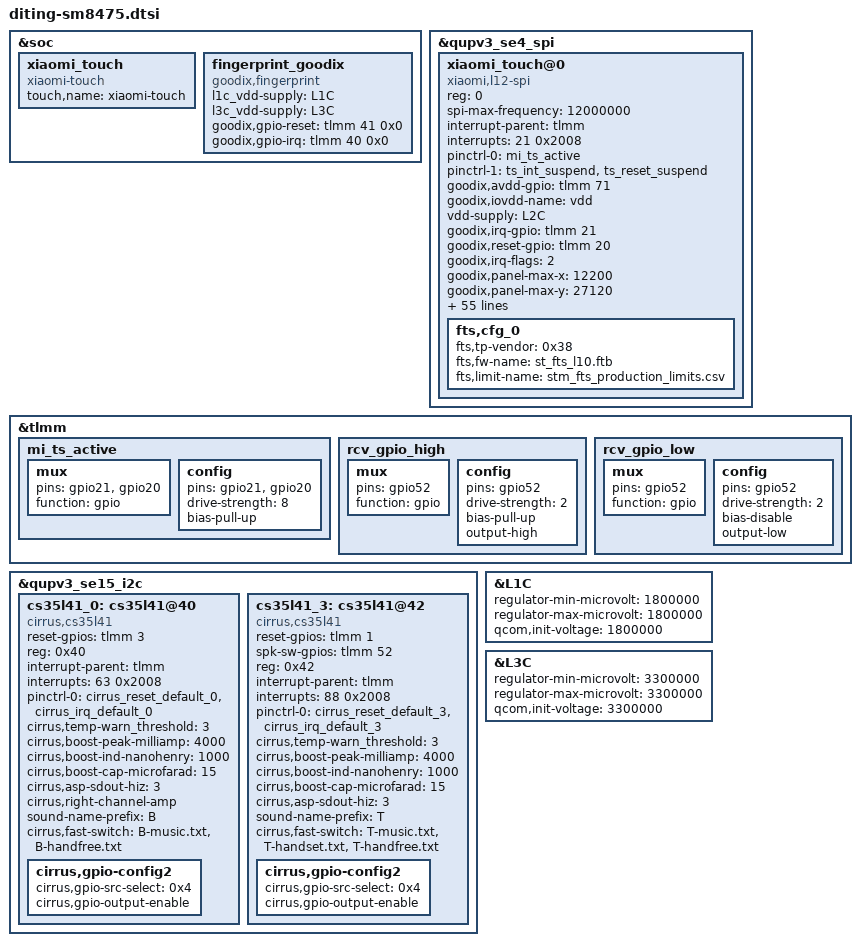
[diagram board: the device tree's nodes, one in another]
/*
   this file is for attribution only of unicorn
   And public attribution of xiaomi platforms(like K2 and so and)
*/
#include "diting-pinctrl.dtsi"
#include "xiaomi-sm8475-common.dtsi"
&soc {
	xiaomi_touch {
		compatible = "xiaomi-touch";
		status = "ok";
		touch,name = "xiaomi-touch";
	};
};
&qupv3_se4_spi {
	status = "ok";
	xiaomi_touch@0 {
		status = "ok";
		compatible = "xiaomi,l12-spi";
		reg = <0>;
		spi-max-frequency = <12000000>;
		interrupt-parent = <&tlmm>;
		interrupts = <21 0x2008>;
		//goodix,avdd-name = "avdd";
		//avdd-supply = <&L7C>;
		pinctrl-names = "pmx_ts_active", "pmx_ts_suspend";
		pinctrl-0 = <&mi_ts_active>;
		pinctrl-1 = <&ts_int_suspend &ts_reset_suspend>;

		goodix,avdd-gpio = <&tlmm 71 0x0>;
		goodix,iovdd-name = "vdd";
		vdd-supply = <&L2C>;
		goodix,irq-gpio = <&tlmm 21 0x2008>;
		goodix,reset-gpio = <&tlmm 20 0x00>;
		goodix,irq-flags = <2>;
		goodix,panel-max-x = <12200>;
		goodix,panel-max-y = <27120>;
		goodix,panel-max-w = <255>;
		goodix,panel-max-p = <4096>;
		goodix,firmware-name = "goodix_firmware_l12.bin";
		goodix,config-name = "goodix_cfg_group_l12.bin";


		fts,avdd-gpio = <&tlmm 71 0x0>;
		//avdd-supply = <&L3C>;
		//vdd-supply = <&L2C>;
		/*panel = <&dsi_k8_42_02_0a_dsc_cmd>;*/
		//fts,pwr-reg-name = "avdd";
		fts,bus-reg-name = "vdd";
		fts,irq-gpio = <&tlmm 21 0x2008>;
		fts,irq-gpio-name = "fts_irq";
		fts,reset-gpio-enable;
		fts,reset-gpio = <&tlmm 20 0x00>;
		fts,reset-gpio-name = "fts_rst";
		fts,irq-flags = <0x2008>;
		fts,x-max = <12200>;
		fts,y-max = <27120>;
		fts,swap-y;
		fts,swap-x;
		fts,support-fod = <1>;
		fts,fod-lx = <4960>;
		fts,fod-ly = <23300>;
		fts,fod-x-size = <2280>;
		fts,fod-y-size = <2280>;
		//spi-max-frequency = <12000000>;
		fts,default-fw-name = "st_fts_l12.ftb";
		//fts,htp-fw-name = "st_fts_l10_thp.ftb";
		fts,non-curved-display = <1>;
		fts,config-array-size = <1>;
		fts,support-super-resolution = <1>;
		fts,touch-follow-performance-def = <3>;
		fts,touch-tap-sensitivity-def = <4>;
		fts,touch-aim-sensitivity-def = <3>;
		fts,touch-tap-stability-def = <3>;
		fts,cornerfilter-area-step1 = <100>;
		fts,cornerfilter-area-step2 = <170>;
		fts,cornerfilter-area-step3 = <250>;
		fts,touch-edgezone-filter-ver = <1 0 0 0 0 0 0 0
						 1 1 0 0 0 0 0 0
						 1 2 0 0 40 2399 0 0
						 1 3 1039 0 1079 2399 0 0>;
		fts,touch-edgezone-filter-hor = <1 0 0 0 1079 40 0 0
						 1 1 0 2359 1079 2399 0 0
						 1 2 0 0 40 2399 0 0
						 1 3 1039 0 1079 2399 0 0>;
		fts,touch-cornerzone-filter-ver = <0 0 0 0 0 0 0 0
						 0 1 0 0 0 0 0 0
						 0 2 0 2099 150 2399 0 0
						 0 3 929 2099 1079 2399 0 0>;
		fts,touch-cornerzone-filter-hor1 = <0 0 0 0 150 150 0 0
						 0 1 0 0 0 0 0 0
						 0 2 0 2249 150 2399 0 0
						 0 3 0 0 0 0 0 0>;
		fts,touch-cornerzone-filter-hor2 = <0 0 0 0 0 0 0 0
						 0 1 929 0 1079 150 0 0
						 0 2 0 0 0 0 0 0
						 0 3 929 2249 1079 2399 0 0>;
		fts,touch-normal-edgezone-filter-hor = <1 0 0 0 1079 30 0 0
						 1 1 0 2369 1079 2399 0 0
						 1 2 0 0 30 2399 0 0
						 1 3 1049 0 1079 2399 0 0>;
		fts,touch-normal-cornerzone-filter-hor1 = <0 0 0 0 170 170 0 0
						 0 1 0 0 0 0 0 0
						 0 2 0 2229 170 2399 0 0
						 0 3 0 0 0 0 0 0>;
		fts,touch-normal-cornerzone-filter-hor2 = <0 0 0 0 0 0 0 0
						 0 1 909 0 1079 170 0 0
						 0 2 0 0 0 0 0 0
						 0 3 909 2229 1079 2399 0 0>;
		fts,touch-follow-performance = <13 15 1
						10 15 1
						8 15 1
						5 15 1
						2 15 1>;
		fts,touch-tap-sensitivity = <160 150 140 120 100>;
		fts,touch-aim-sensitivity = <8 6 4 2 1>;
		fts,touch-tap-stability = <8 12 15 18 25>;
		fts,touch-expert-array = <6 15 1 120 6 15
					  2 15 1 120 4 15
					  4 15 1 120 2 15>;
		fts,cfg_0 {
			fts,tp-vendor = <0x38>;
			fts,fw-name = "st_fts_l10.ftb";
			fts,limit-name = "stm_fts_production_limits.csv";
		};
	};
};
&tlmm {
        mi_ts_active: mi_ts_active {
                mux {
                                pins = "gpio21", "gpio20";
                                function = "gpio";
                };
		config {
                                pins = "gpio21", "gpio20";
                                drive-strength = <8>;
                                bias-pull-up;
                };
        };
	/* RCV HANDSET CTL */
	rcv_gpio_high: rcv_gpio_high {
		mux {
			pins = "gpio52";
			function = "gpio";
		};

		config {
			pins = "gpio52";
			drive-strength = <2>;
			bias-pull-up;
			output-high;
		};
	};
	rcv_gpio_low: rcv_gpio_low {
		mux {
			pins = "gpio52";
			function = "gpio";
		};

		config {
			pins = "gpio52";
			drive-strength = <2>;
			bias-disable;
			output-low;
		};
	};
};

&qupv3_se15_i2c {
	status = "ok";
	cs35l41_0: cs35l41@40 {
		status = "ok";
		compatible = "cirrus,cs35l41";
		reset-gpios = <&tlmm 3 0>;
		reg = <0x40>;
		interrupt-parent = <&tlmm>;
		interrupts = <63 0x2008>;
		pinctrl-names = "default";
		pinctrl-0 = <&cirrus_reset_default_0 &cirrus_irq_default_0>;
		cirrus,temp-warn_threshold = <3>;
		cirrus,boost-peak-milliamp = <4000>;
		cirrus,boost-ind-nanohenry = <1000>;
		cirrus,boost-cap-microfarad = <15>;
		cirrus,asp-sdout-hiz = <3>;
		cirrus,right-channel-amp;
		sound-name-prefix = "B";
		cirrus,fast-switch = "B-music.txt", "B-handfree.txt";
		cirrus,gpio-config2 {
			cirrus,gpio-src-select = <0x4>;
			cirrus,gpio-output-enable;
		};
	};
	cs35l41_3: cs35l41@42 {
		status = "ok";
		compatible = "cirrus,cs35l41";
		reset-gpios = <&tlmm 1 0>;
		spk-sw-gpios = <&tlmm 52 0>;
		reg = <0x42>;
		interrupt-parent = <&tlmm>;
		interrupts = <88 0x2008>;
		pinctrl-names = "default";
		pinctrl-0 = <&cirrus_reset_default_3 &cirrus_irq_default_3>;
		cirrus,temp-warn_threshold = <3>;
		cirrus,boost-peak-milliamp = <4000>;
		cirrus,boost-ind-nanohenry = <1000>;
		cirrus,boost-cap-microfarad = <15>;
		cirrus,asp-sdout-hiz = <3>;
		sound-name-prefix = "T";
		cirrus,fast-switch = "T-music.txt", "T-handset.txt", "T-handfree.txt";
		cirrus,gpio-config2 {
			cirrus,gpio-src-select = <0x4>;
			cirrus,gpio-output-enable;
		};
	};
};

&soc {
	fingerprint_goodix {
		compatible = "goodix,fingerprint";
		l1c_vdd-supply = <&L1C>;
                l3c_vdd-supply = <&L3C>;
		goodix,gpio-reset = <&tlmm 41 0x0>;
		goodix,gpio-irq = <&tlmm 40 0x0>;
		status = "ok";
	};
};
&L1C {
	regulator-min-microvolt = <1800000>;
	regulator-max-microvolt = <1800000>;
	qcom,init-voltage = <1800000>;
};

&L3C {
	regulator-min-microvolt = <3300000>;
	regulator-max-microvolt = <3300000>;
	qcom,init-voltage = <3300000>;
};

